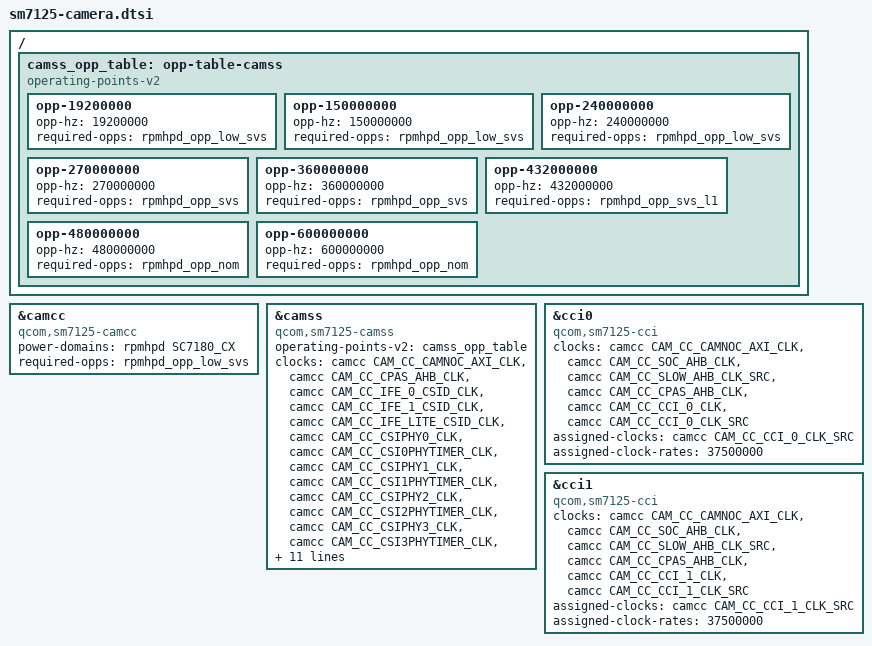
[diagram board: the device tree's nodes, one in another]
// SPDX-License-Identifier: GPL-2.0
/*
 * SM7125 camera override
 */

#include <dt-bindings/clock/qcom,camcc-sm7125.h>

&camcc {
	compatible = "qcom,sm7125-camcc";
	power-domains = <&rpmhpd SC7180_CX>;
	required-opps = <&rpmhpd_opp_low_svs>;
};

&camss {
	compatible = "qcom,sm7125-camss";
	status = "okay";
	operating-points-v2 = <&camss_opp_table>;
	clocks = <&camcc CAM_CC_CAMNOC_AXI_CLK>,
		 <&camcc CAM_CC_CPAS_AHB_CLK>,
		 <&camcc CAM_CC_IFE_0_CSID_CLK>,
		 <&camcc CAM_CC_IFE_1_CSID_CLK>,
		 <&camcc CAM_CC_IFE_LITE_CSID_CLK>,
		 <&camcc CAM_CC_CSIPHY0_CLK>,
		 <&camcc CAM_CC_CSI0PHYTIMER_CLK>,
		 <&camcc CAM_CC_CSIPHY1_CLK>,
		 <&camcc CAM_CC_CSI1PHYTIMER_CLK>,
		 <&camcc CAM_CC_CSIPHY2_CLK>,
		 <&camcc CAM_CC_CSI2PHYTIMER_CLK>,
		 <&camcc CAM_CC_CSIPHY3_CLK>,
		 <&camcc CAM_CC_CSI3PHYTIMER_CLK>,
		 <&gcc GCC_CAMERA_AHB_CLK>,
		 <&gcc GCC_CAMERA_HF_AXI_CLK>,
		 <&camcc CAM_CC_SOC_AHB_CLK>,
		 <&camcc CAM_CC_IFE_0_AXI_CLK>,
		 <&camcc CAM_CC_IFE_0_CLK>,
		 <&camcc CAM_CC_IFE_0_CPHY_RX_CLK>,
		 <&camcc CAM_CC_IFE_1_AXI_CLK>,
		 <&camcc CAM_CC_IFE_1_CLK>,
		 <&camcc CAM_CC_IFE_1_CPHY_RX_CLK>,
		 <&camcc CAM_CC_IFE_LITE_CLK>,
		 <&camcc CAM_CC_IFE_LITE_CPHY_RX_CLK>;
};

/ {
	camss_opp_table: opp-table-camss {
		compatible = "operating-points-v2";

		opp-19200000 {
			opp-hz = /bits/ 64 <19200000>;
			required-opps = <&rpmhpd_opp_low_svs>;
		};
		opp-150000000 {
			opp-hz = /bits/ 64 <150000000>;
			required-opps = <&rpmhpd_opp_low_svs>;
		};
		opp-240000000 {
			opp-hz = /bits/ 64 <240000000>;
			required-opps = <&rpmhpd_opp_low_svs>;
		};
		opp-270000000 {
			opp-hz = /bits/ 64 <270000000>;
			required-opps = <&rpmhpd_opp_svs>;
		};
		opp-360000000 {
			opp-hz = /bits/ 64 <360000000>;
			required-opps = <&rpmhpd_opp_svs>;
		};
		opp-432000000 {
			opp-hz = /bits/ 64 <432000000>;
			required-opps = <&rpmhpd_opp_svs_l1>;
		};
		opp-480000000 {
			opp-hz = /bits/ 64 <480000000>;
			required-opps = <&rpmhpd_opp_nom>;
		};
		opp-600000000 {
			opp-hz = /bits/ 64 <600000000>;
			required-opps = <&rpmhpd_opp_nom>;
		};
	};
};

&cci0 {
	compatible = "qcom,sm7125-cci", "qcom,msm8996-cci";
	status = "okay";
	clocks = <&camcc CAM_CC_CAMNOC_AXI_CLK>,
		 <&camcc CAM_CC_SOC_AHB_CLK>,
		 <&camcc CAM_CC_SLOW_AHB_CLK_SRC>,
		 <&camcc CAM_CC_CPAS_AHB_CLK>,
		 <&camcc CAM_CC_CCI_0_CLK>,
		 <&camcc CAM_CC_CCI_0_CLK_SRC>;
	assigned-clocks = <&camcc CAM_CC_CCI_0_CLK_SRC>;
	assigned-clock-rates = <37500000>;
};

&cci1 {
	compatible = "qcom,sm7125-cci", "qcom,msm8996-cci";
	status = "okay";
	clocks = <&camcc CAM_CC_CAMNOC_AXI_CLK>,
		 <&camcc CAM_CC_SOC_AHB_CLK>,
		 <&camcc CAM_CC_SLOW_AHB_CLK_SRC>,
		 <&camcc CAM_CC_CPAS_AHB_CLK>,
		 <&camcc CAM_CC_CCI_1_CLK>,
		 <&camcc CAM_CC_CCI_1_CLK_SRC>;
	assigned-clocks = <&camcc CAM_CC_CCI_1_CLK_SRC>;
	assigned-clock-rates = <37500000>;
};
